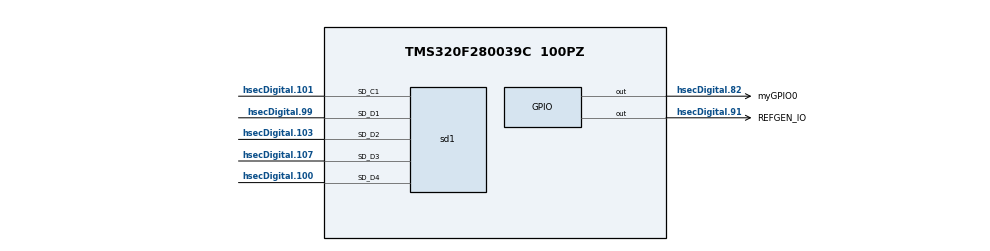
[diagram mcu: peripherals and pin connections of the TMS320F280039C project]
/**
 * These arguments were used when this file was generated. They will be automatically applied on subsequent loads
 * via the GUI or CLI. Run CLI with '--help' for additional information on how to override these arguments.
 * @cliArgs --board "/boards/TMDSCNCD280039C" --device "F28003x" --part "F28003x_100PZ" --package "100PZ" --context "system" --product "C2000WARE@5.04.00.00"
 * @v2CliArgs --device "TMS320F280039C" --package "100PZ" --board "/boards/TMDSCNCD280039C" --context "system" --product "C2000WARE@5.04.00.00"
 * @versions {"tool":"1.21.0+3721"}
 */

/**
 * Import the modules used in this configuration.
 */
const adc            = scripting.addModule("/driverlib/adc.js", {}, false);
const adc1           = adc.addInstance();
const analog         = scripting.addModule("/driverlib/analog.js", {}, false);
const analog1        = analog.addInstance();
const asysctl        = scripting.addModule("/driverlib/asysctl.js");
const cla            = scripting.addModule("/driverlib/cla.js", {}, false);
const cla1           = cla.addInstance();
const cputimer       = scripting.addModule("/driverlib/cputimer.js", {}, false);
const cputimer1      = cputimer.addInstance();
const cputimer2      = cputimer.addInstance();
const device_support = scripting.addModule("/driverlib/device_support.js");
const epwm           = scripting.addModule("/driverlib/epwm.js", {}, false);
const epwm1          = epwm.addInstance();
const epwm2          = epwm.addInstance();
const epwm3          = epwm.addInstance();
const epwm4          = epwm.addInstance();
const epwm5          = epwm.addInstance();
const gpio           = scripting.addModule("/driverlib/gpio.js", {}, false);
const gpio1          = gpio.addInstance();
const gpio2          = gpio.addInstance();
const memcfg         = scripting.addModule("/driverlib/memcfg.js");
const sd             = scripting.addModule("/driverlib/sd.js", {}, false);
const sd1            = sd.addInstance();
const sync           = scripting.addModule("/driverlib/sync.js");
const sfo            = scripting.addModule("/libraries/calibration/hrpwm/sfo.js", {}, false);
const sfo1           = sfo.addInstance();
const controller     = scripting.addModule("/libraries/control/dcl/controller.js", {}, false);
const controller1    = controller.addInstance();
const refgen         = scripting.addModule("/libraries/control/dcl/refgen.js", {}, false);
const refgen1        = refgen.addInstance();
const CMD            = scripting.addModule("/utilities/cmd_tool/cmd_syscfg/source/CMD");
const CMD1           = CMD.addInstance();
const CMD2           = CMD.addInstance();

/**
 * Write custom configuration values to the imported modules.
 */
adc1.$name                   = "myADC0";
adc1.adcClockPrescaler       = "ADC_CLK_DIV_2_0";
adc1.enabledSOCs             = ["ADC_SOC_NUMBER0"];
adc1.soc0SampleWindow        = 9;
adc1.interruptPulseMode      = "ADC_PULSE_END_OF_CONV";
adc1.enabledInts             = ["ADC_INT_NUMBER1"];
adc1.enableInterrupt1        = true;
adc1.registerInterrupts      = ["1"];
adc1.adcBase                 = "ADCB_BASE";
adc1.soc0Channel             = "ADC_CH_ADCIN2";
adc1.soc0Trigger             = "ADC_TRIGGER_EPWM3_SOCA";
adc1.adcInt1.enableInterrupt = true;

analog1.$name                      = "myANALOGPinMux0";
adc1.analog                        = analog1;
analog1.useCase                    = "CUSTOM";
analog1.useInterfacePins           = ["B2/C6"];
analog1.analog.$assign             = "ANALOG";
analog1.analog["b2/c6Pin"].$assign = "hsecAnalog.14";

asysctl.analogReference        = "INTERNAL";
asysctl.analogReferenceVoltage = "1P65";

cla1.$name             = "myCLA0";
cla1.enable_CLA_TASK_2 = false;
cla1.enable_CLA_TASK_3 = false;
cla1.enable_CLA_TASK_4 = false;
cla1.enable_CLA_TASK_5 = false;
cla1.enable_CLA_TASK_6 = false;
cla1.enable_CLA_TASK_7 = false;
cla1.cpuint_CLA_TASK_2 = false;
cla1.cpuint_CLA_TASK_3 = false;
cla1.cpuint_CLA_TASK_4 = false;
cla1.cpuint_CLA_TASK_5 = false;
cla1.cpuint_CLA_TASK_6 = false;
cla1.cpuint_CLA_TASK_7 = false;
cla1.enable_CLA_TASK_8 = false;
cla1.cpuint_CLA_TASK_8 = false;

const divider5       = system.clockTree["PLL_REFDIV"];
divider5.divideValue = 2;

const mux3       = system.clockTree["OSCCLKSRCSEL"];
mux3.inputSelect = "X1_XTAL";

cputimer1.$name       = "myCPUTIMER0";
cputimer1.timerPeriod = 1200;
cputimer1.startTimer  = true;

cputimer2.$name        = "myCPUTIMER1";
cputimer2.cputimerBase = "CPUTIMER1_BASE";
cputimer2.timerPeriod  = 1200000;
cputimer2.startTimer   = true;

epwm1.$name                                           = "myEPWM0";
epwm1.$hardware                                       = system.deviceData.board.components.PWM_LOC1;
epwm1.epwmTimebase_hsClockDiv                         = "EPWM_HSCLOCK_DIVIDER_1";
epwm1.epwmDeadband_enableRED                          = true;
epwm1.epwmDeadband_enableFED                          = true;
epwm1.epwmCounterCompare_shadowLoadModeCMPA           = "EPWM_COMP_LOAD_ON_CNTR_ZERO_PERIOD";
epwm1.epwmCounterCompare_shadowLoadModeCMPB           = "EPWM_COMP_LOAD_ON_CNTR_ZERO_PERIOD";
epwm1.hrpwm_HRLoadA                                   = "HRPWM_LOAD_ON_CNTR_ZERO_PERIOD";
epwm1.hrpwm_HRLoadB                                   = "HRPWM_LOAD_ON_CNTR_ZERO_PERIOD";
epwm1.epwmDeadband_polarityFED                        = "EPWM_DB_POLARITY_ACTIVE_LOW";
epwm1.epwmDeadband_delayRED                           = 12;
epwm1.epwmDeadband_delayFED                           = 12;
epwm1.epwmActionQualifier_EPWM_AQ_OUTPUT_A_shadowMode = true;
epwm1.epwmActionQualifier_EPWM_AQ_OUTPUT_B_shadowMode = true;
epwm1.epwmGlobalLoad_gld                              = true;
epwm1.epwmGlobalLoad_enableOneShot                    = true;
epwm1.epwmGlobalLoad_oneShotMode                      = true;
epwm1.epwmGlobalLoad_globalePWMLoadLink               = "EPWM_LINK_WITH_EPWM_1";
epwm1.epwmTimebase_periodGld                          = true;
epwm1.epwmCounterCompare_cmpAGld                      = true;
epwm1.epwmCounterCompare_cmpALink                     = "EPWM_LINK_WITH_EPWM_1";
epwm1.epwmTimebase_syncInPulseSource                  = "EPWM_SYNC_IN_PULSE_SRC_DISABLE";
epwm1.epwmCounterCompare_cmpCGld                      = true;
epwm1.epwmCounterCompare_cmpCLink                     = "EPWM_LINK_WITH_EPWM_1";
epwm1.epwmTimebase_syncOutPulseMode                   = ["EPWM_SYNC_OUT_PULSE_ON_CNTR_ZERO"];
epwm1.epwmCounterCompare_cmpC                         = 150;
epwm1.epwmTimebase_period                             = 600;
epwm1.epwmTimebase_counterMode                        = "EPWM_COUNTER_MODE_UP_DOWN";
epwm1.epwmActionQualifier_EPWM_AQ_OUTPUT_A_gld        = true;
epwm1.epwmCounterCompare_cmpBGld                      = true;
epwm1.epwmCounterCompare_cmpBLink                     = "EPWM_LINK_WITH_EPWM_1";
epwm1.epwmCounterCompare_cmpA                         = 300;
epwm1.epwmCounterCompare_cmpB                         = 300;

epwm2.$name                                           = "myEPWM1";
epwm2.$hardware                                       = system.deviceData.board.components.PWM_LOC2;
epwm2.epwmTimebase_phaseEnable                        = true;
epwm2.epwmTimebase_hsClockDiv                         = "EPWM_HSCLOCK_DIVIDER_1";
epwm2.epwmDeadband_polarityFED                        = "EPWM_DB_POLARITY_ACTIVE_LOW";
epwm2.epwmDeadband_enableRED                          = true;
epwm2.epwmDeadband_enableFED                          = true;
epwm2.epwmTimebase_syncOutPulseMode                   = ["EPWM_SYNC_OUT_PULSE_ON_CNTR_ZERO"];
epwm2.epwmCounterCompare_shadowLoadModeCMPB           = "EPWM_COMP_LOAD_ON_CNTR_ZERO_PERIOD";
epwm2.epwmDeadband_delayRED                           = 12;
epwm2.epwmDeadband_delayFED                           = 12;
epwm2.epwmActionQualifier_EPWM_AQ_OUTPUT_B_shadowMode = true;
epwm2.epwmCounterCompare_cmpAGld                      = true;
epwm2.epwmCounterCompare_cmpALink                     = "EPWM_LINK_WITH_EPWM_1";
epwm2.epwmTimebase_periodLoadEvent                    = "EPWM_SHADOW_LOAD_MODE_SYNC";
epwm2.epwmTimebase_periodLink                         = "EPWM_LINK_WITH_EPWM_1";
epwm2.epwmCounterCompare_cmpCGld                      = true;
epwm2.epwmCounterCompare_cmpCLink                     = "EPWM_LINK_WITH_EPWM_1";
epwm2.epwmCounterCompare_shadowLoadModeCMPA           = "EPWM_COMP_LOAD_ON_CNTR_ZERO_PERIOD";
epwm2.epwmCounterCompare_cmpC                         = 150;
epwm2.epwmTimebase_period                             = 600;
epwm2.epwmTimebase_counterMode                        = "EPWM_COUNTER_MODE_UP_DOWN";
epwm2.epwmTimebase_phaseShift                         = 598;
epwm2.epwmGlobalLoad_gld                              = true;
epwm2.epwmGlobalLoad_enableOneShot                    = true;
epwm2.epwmGlobalLoad_oneShotMode                      = true;
epwm2.epwmGlobalLoad_globalePWMLoadLink               = "EPWM_LINK_WITH_EPWM_1";
epwm2.epwmGlobalLoad_oneShotForce                     = true;
epwm2.epwmActionQualifier_EPWM_AQ_OUTPUT_A_gld        = true;
epwm2.epwmActionQualifier_EPWM_AQ_OUTPUT_A_shadowMode = true;
epwm2.epwmCounterCompare_cmpBGld                      = true;
epwm2.epwmCounterCompare_cmpBLink                     = "EPWM_LINK_WITH_EPWM_1";
epwm2.epwmCounterCompare_cmpA                         = 300;
epwm2.epwmCounterCompare_cmpB                         = 300;

epwm3.$name                                                      = "myEPWM2";
epwm3.epwmTimebase_hsClockDiv                                    = "EPWM_HSCLOCK_DIVIDER_1";
epwm3.epwmTimebase_period                                        = 600;
epwm3.epwmTimebase_counterMode                                   = "EPWM_COUNTER_MODE_UP_DOWN";
epwm3.epwmCounterCompare_cmpA                                    = 300;
epwm3.epwmDeadband_polarityFED                                   = "EPWM_DB_POLARITY_ACTIVE_LOW";
epwm3.epwmDeadband_enableRED                                     = true;
epwm3.epwmDeadband_enableFED                                     = true;
epwm3.$hardware                                                  = system.deviceData.board.components.PWM_LOC3;
epwm3.epwmCounterCompare_cmpB                                    = 300;
epwm3.epwmActionQualifier_EPWM_AQ_OUTPUT_A_ON_TIMEBASE_UP_CMPA   = "EPWM_AQ_OUTPUT_HIGH";
epwm3.hrpwm_enable                                               = true;
epwm3.hrpwm_autoConv                                             = true;
epwm3.hrpwm_epwmclk                                              = 120;
epwm3.hrpwm_period                                               = 10000;
epwm3.hrpwm_periodEnable                                         = true;
epwm3.hrpwm_HRLoadA                                              = "HRPWM_LOAD_ON_CNTR_ZERO_PERIOD";
epwm3.hrpwm_edgeModeB                                            = "HRPWM_MEP_CTRL_RISING_AND_FALLING_EDGE";
epwm3.hrpwm_HRLoadB                                              = "HRPWM_LOAD_ON_CNTR_ZERO_PERIOD";
epwm3.epwmActionQualifier_EPWM_AQ_OUTPUT_A_ON_TIMEBASE_DOWN_CMPA = "EPWM_AQ_OUTPUT_LOW";
epwm3.epwmActionQualifier_EPWM_AQ_OUTPUT_B_ON_TIMEBASE_UP_CMPB   = "EPWM_AQ_OUTPUT_HIGH";
epwm3.epwmActionQualifier_EPWM_AQ_OUTPUT_B_ON_TIMEBASE_DOWN_CMPB = "EPWM_AQ_OUTPUT_LOW";
epwm3.epwmCounterCompare_shadowLoadModeCMPA                      = "EPWM_COMP_LOAD_ON_CNTR_ZERO_PERIOD";
epwm3.epwmCounterCompare_shadowLoadModeCMPB                      = "EPWM_COMP_LOAD_ON_CNTR_ZERO_PERIOD";
epwm3.hrpwm_edgeModeA                                            = "HRPWM_MEP_CTRL_RISING_AND_FALLING_EDGE";
epwm3.epwmTimebase_syncOutPulseMode                              = ["EPWM_SYNC_OUT_PULSE_ON_CNTR_ZERO"];
epwm3.epwmEventTrigger_EPWM_SOC_A_triggerEnable                  = true;
epwm3.epwmEventTrigger_EPWM_SOC_A_triggerEventPrescalar          = "1";
epwm3.epwmCounterCompare_cmpC                                    = 400;
epwm3.epwmDeadband_delayRED                                      = 12;
epwm3.epwmDeadband_delayFED                                      = 12;
epwm3.epwmEventTrigger_EPWM_SOC_A_triggerSource                  = "EPWM_SOC_TBCTR_U_CMPD";
epwm3.epwmCounterCompare_cmpD                                    = 599;
epwm3.epwmTimebase_periodLoadEvent                               = "EPWM_SHADOW_LOAD_MODE_SYNC";
epwm3.epwmActionQualifier_EPWM_AQ_OUTPUT_A_shadowMode            = true;
epwm3.epwmActionQualifier_EPWM_AQ_OUTPUT_A_gld                   = true;
epwm3.epwmActionQualifier_EPWM_AQ_OUTPUT_B_shadowMode            = true;
epwm3.epwmActionQualifier_EPWM_AQ_OUTPUT_B_gld                   = true;

epwm4.$name                                                      = "myEPWM3";
epwm4.$hardware                                                  = system.deviceData.board.components.PWM_LOC4;
epwm4.epwmTimebase_hsClockDiv                                    = "EPWM_HSCLOCK_DIVIDER_1";
epwm4.epwmTimebase_period                                        = 600;
epwm4.epwmTimebase_counterMode                                   = "EPWM_COUNTER_MODE_UP_DOWN";
epwm4.epwmCounterCompare_cmpA                                    = 300;
epwm4.epwmDeadband_polarityFED                                   = "EPWM_DB_POLARITY_ACTIVE_LOW";
epwm4.epwmDeadband_enableRED                                     = true;
epwm4.epwmDeadband_enableFED                                     = true;
epwm4.epwmCounterCompare_cmpB                                    = 300;
epwm4.epwmCounterCompare_shadowLoadModeCMPA                      = "EPWM_COMP_LOAD_ON_CNTR_ZERO_PERIOD";
epwm4.epwmCounterCompare_shadowLoadModeCMPB                      = "EPWM_COMP_LOAD_ON_CNTR_ZERO_PERIOD";
epwm4.epwmActionQualifier_EPWM_AQ_OUTPUT_A_ON_TIMEBASE_DOWN_CMPA = "EPWM_AQ_OUTPUT_LOW";
epwm4.epwmActionQualifier_EPWM_AQ_OUTPUT_B_ON_TIMEBASE_UP_CMPB   = "EPWM_AQ_OUTPUT_HIGH";
epwm4.epwmActionQualifier_EPWM_AQ_OUTPUT_B_ON_TIMEBASE_DOWN_CMPB = "EPWM_AQ_OUTPUT_LOW";
epwm4.hrpwm_edgeModeA                                            = "HRPWM_MEP_CTRL_RISING_AND_FALLING_EDGE";
epwm4.hrpwm_edgeModeB                                            = "HRPWM_MEP_CTRL_RISING_AND_FALLING_EDGE";
epwm4.hrpwm_HRLoadB                                              = "HRPWM_LOAD_ON_CNTR_ZERO_PERIOD";
epwm4.hrpwm_HRLoadA                                              = "HRPWM_LOAD_ON_CNTR_ZERO_PERIOD";
epwm4.hrpwm_enable                                               = true;
epwm4.hrpwm_autoConv                                             = true;
epwm4.hrpwm_periodEnable                                         = true;
epwm4.epwmTimebase_syncOutPulseMode                              = ["EPWM_SYNC_OUT_PULSE_ON_CNTR_ZERO"];
epwm4.epwmActionQualifier_EPWM_AQ_OUTPUT_A_ON_TIMEBASE_UP_CMPA   = "EPWM_AQ_OUTPUT_HIGH";
epwm4.epwmDeadband_delayRED                                      = 12;
epwm4.epwmDeadband_delayFED                                      = 12;
epwm4.epwmDeadband_outputSwapOutA                                = true;
epwm4.epwmDeadband_outputSwapOutB                                = true;
epwm4.epwmActionQualifier_EPWM_AQ_OUTPUT_A_shadowMode            = true;
epwm4.epwmActionQualifier_EPWM_AQ_OUTPUT_B_shadowMode            = true;
epwm4.epwmTimebase_periodLoadEvent                               = "EPWM_SHADOW_LOAD_MODE_SYNC";

epwm5.$name                                                    = "myEPWM4";
epwm5.$hardware                                                = system.deviceData.board.components.PWM_LOC5;
epwm5.epwmTimebase_hsClockDiv                                  = "EPWM_HSCLOCK_DIVIDER_1";
epwm5.epwmTimebase_period                                      = 3;
epwm5.epwmCounterCompare_cmpA                                  = 3;
epwm5.epwmCounterCompare_cmpB                                  = 3;
epwm5.epwmActionQualifier_EPWM_AQ_OUTPUT_A_ON_TIMEBASE_ZERO    = "EPWM_AQ_OUTPUT_LOW";
epwm5.epwmDeadband_enableRED                                   = true;
epwm5.epwmDeadband_enableFED                                   = true;
epwm5.epwmTimebase_emulationMode                               = "EPWM_EMULATION_FREE_RUN";
epwm5.epwmTimebase_counterMode                                 = "EPWM_COUNTER_MODE_UP_DOWN";
epwm5.epwmTimebase_syncInPulseSource                           = "EPWM_SYNC_IN_PULSE_SRC_DISABLE";
epwm5.epwmActionQualifier_EPWM_AQ_OUTPUT_A_ON_TIMEBASE_UP_CMPA = "EPWM_AQ_OUTPUT_HIGH";

gpio1.$name             = "myGPIO0";
gpio1.writeInitialValue = true;
gpio1.initialValue      = 1;
gpio1.direction         = "GPIO_DIR_MODE_OUT";
gpio1.gpioPin.$assign   = "hsecDigital.82";
scripting.suppress("Connected to hardware,@@@.+?@@@ is connected to CANA on the Control Card F280039C\\. Consider selecting it in \'use hardware\' above\\. @@@.+?@@@", gpio1, "gpioPin");

gpio2.$name           = "REFGEN_IO";
gpio2.direction       = "GPIO_DIR_MODE_OUT";
gpio2.gpioPin.$assign = "hsecDigital.91";

memcfg.config_MEMCFG_SECT_LS0        = "CLA_prog";
memcfg.config_MEMCFG_SECT_LS1        = "CLA_data";
memcfg.init_MEMCFG_SECT_MSGCPUTOCLA1 = true;
memcfg.init_MEMCFG_SECT_MSGCLA1TOCPU = true;

sd1.$name                         = "mySDFM0";
sd1.Use_FilterChannel_1           = true;
sd1.Ch1_DataFilterEnable          = true;
sd1.useInterrupts                 = true;
sd1.Ch1_DataFilter_Representation = "SDFM_DATA_FORMAT_16_BIT";
sd1.Ch1_DOSR                      = 128;
sd1.useCase                       = "SINGLE CLOCK";
sd1.Ch1_FIFO_Enable               = true;
sd1.Ch1_SDFFIL                    = "16";
sd1.SDFFINT                       = ["FILTER1"];
sd1.registerInterrupts            = ["INT_SDFM_DR1"];
sd1.sd.sd_c1Pin.$assign           = "hsecDigital.101";
sd1.sd.sd_d1Pin.$assign           = "hsecDigital.99";
sd1.sd.sd_d2Pin.$assign           = "hsecDigital.103";
sd1.sd.sd_d3Pin.$assign           = "hsecDigital.107";
sd1.sd.sd_d4Pin.$assign           = "hsecDigital.100";
sd1.sdfmIntDr1.enableInterrupt    = true;
scripting.suppress("Connected to hardware,@@@.+?@@@ is connected to EQEP2 on the Control Card F280039C\\. Consider selecting it in \'use hardware\' above\\. @@@.+?@@@", sd1.sd, "sd_d4Pin");

sfo1.$name = "mySFO0";

controller1.$name            = "PI_CONTROLLER";
controller1.controllerChoice = "PI";
controller1.Umax             = "0.25f";
controller1.Umin             = "-0.25f";
controller1.Imax             = "0.25f";
controller1.Imin             = "-0.25f";
controller1.Kp               = "0.0001f";
controller1.Ki               = "0.6f";

refgen1.$name = "myREFGEN0";
refgen1.ampl  = 10;
refgen1.offs  = 0;
refgen1.freq  = 1000;
refgen1.mode  = "STATIC";
refgen1.umax  = 120;

CMD.activateCMD = true;
CMD.activeCMD   = "CMD_RAM";

CMD1.$name                             = "CMD_RAM";
CMD1.sectionMemory_ramfunc             = ["RAMM0"];
CMD1.sectionMemory_cinit               = ["RAMM0"];
CMD1.sectionMemory_switch              = ["RAMM0"];
CMD1.sectionMemory_stack               = ["RAMM1"];
CMD1.sectionMemory_bss                 = ["RAMLS5"];
CMD1.sectionMemory_init_array          = ["RAMM0"];
CMD1.sectionMemory_sysmem              = ["RAMGS2"];
CMD1.sectionMemory_data                = ["RAMGS0"];
CMD1.sectionMemory_text                = ["RAMGS3","RAMLS3","RAMLS4","RAMLS5","RAMLS6","RAMLS7"];
CMD1.sectionMemory_cla1Prog            = ["RAMLS0"];
CMD1.sectionMemory_claConst            = ["RAMLS1"];
CMD1.sectionMemory_claScratchpad       = ["RAMLS1"];
CMD1.sectionMemory_cla1ToCpuMsgRAM     = ["CLATOCPU_MSGRAM"];
CMD1.sectionMemory_bssCla              = ["RAMLS1"];
CMD1.sectionMemory_cpuToCla1MsgRAM     = ["CPUTOCLA_MSGRAM"];
CMD1.sectionMemory_const               = ["RAMGS2"];
CMD1.userSection.create(1);
CMD1.userSection[0].sectionName        = "dclfuncs";
CMD1.userSection[0].$name              = "dclfuncs_RAM";
CMD1.userSection[0].sectionAlignEnable = true;
CMD1.userSection[0].sectionAlign       = 2;
CMD1.userSection[0].sectionMemory      = ["RAMGS1"];

CMD2.$name                                      = "CMD_FLASH";
CMD2.sectionMemory_ramfunc                      = ["FLASH_BANK0_SEC1"];
CMD2.sectionAlignEnable_ramfunc                 = true;
CMD2.sectionRunFromDifferentAddr_ramfunc        = true;
CMD2.sectionMemory_text                         = ["FLASH_BANK0_SEC2","FLASH_BANK0_SEC3","FLASH_BANK0_SEC4"];
CMD2.sectionAlignEnable_text                    = true;
CMD2.sectionMemory_binit                        = ["FLASH_BANK0_SEC1"];
CMD2.sectionAlignEnable_binit                   = true;
CMD2.sectionMemory_cinit                        = ["FLASH_BANK0_SEC1"];
CMD2.sectionAlignEnable_cinit                   = true;
CMD2.sectionMemory_switch                       = ["FLASH_BANK0_SEC1"];
CMD2.sectionAlignEnable_switch                  = true;
CMD2.sectionMemory_stack                        = ["RAMM1"];
CMD2.sectionMemory_bss                          = ["RAMLS5"];
CMD2.sectionMemory_init_array                   = ["FLASH_BANK0_SEC1"];
CMD2.sectionAlignEnable_init_array              = true;
CMD2.sectionMemory_const                        = ["FLASH_BANK0_SEC4"];
CMD2.sectionAlignEnable_const                   = true;
CMD2.sectionMemory_data                         = ["RAMLS5"];
CMD2.sectionMemory_sysmem                       = ["RAMLS5"];
CMD2.sectionMemory_ovly                         = ["FLASH_BANK0_SEC1"];
CMD2.sectionAlignEnable_ovly                    = true;
CMD2.sectionMemory_codestart                    = "0x080000";
CMD2.sectionRun_ramfunc                         = ["RAMLS3"];
CMD2.userSection.create(1);
CMD2.userSection[0].sectionName                 = "dclfuncs";
CMD2.userSection[0].sectionRunFromDifferentAddr = true;
CMD2.userSection[0].sectionAlignEnable          = true;
CMD2.userSection[0].sectionRun                  = ["RAMLS7"];
CMD2.userSection[0].sectionMemory               = ["FLASH_BANK2_SEC10"];
CMD2.userSection[0].$name                       = "dclfuncs_FLASH";
CMD2.userSection[0].sectionBinit                = false;

/**
 * Pinmux solution for unlocked pins/peripherals. This ensures that minor changes to the automatic solver in a future
 * version of the tool will not impact the pinmux you originally saw.  These lines can be completely deleted in order to
 * re-solve from scratch.
 */
epwm1.epwm.$suggestSolution           = "EPWM1";
epwm1.epwm.epwm_aPin.$suggestSolution = "hsecDigital.49";
epwm1.epwm.epwm_bPin.$suggestSolution = "hsecDigital.51";
epwm2.epwm.$suggestSolution           = "EPWM2";
epwm2.epwm.epwm_aPin.$suggestSolution = "hsecDigital.53";
epwm2.epwm.epwm_bPin.$suggestSolution = "hsecDigital.55";
epwm3.epwm.$suggestSolution           = "EPWM3";
epwm3.epwm.epwm_aPin.$suggestSolution = "hsecDigital.50";
epwm3.epwm.epwm_bPin.$suggestSolution = "hsecDigital.52";
epwm4.epwm.$suggestSolution           = "EPWM4";
epwm4.epwm.epwm_aPin.$suggestSolution = "hsecDigital.54";
epwm4.epwm.epwm_bPin.$suggestSolution = "hsecDigital.56";
epwm5.epwm.$suggestSolution           = "EPWM5";
epwm5.epwm.epwm_aPin.$suggestSolution = "hsecDigital.57";
epwm5.epwm.epwm_bPin.$suggestSolution = "hsecDigital.59";
sd1.sd.$suggestSolution               = "SD1";
